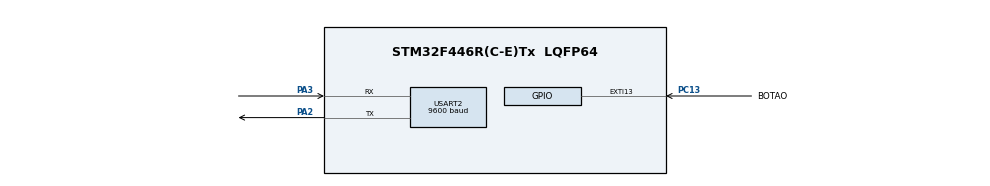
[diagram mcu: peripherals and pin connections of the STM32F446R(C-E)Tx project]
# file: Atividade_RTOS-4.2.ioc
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FREERTOS.CountingSemaphores01=MeuSemaforoContador,2,Dynamic,NULL,0
FREERTOS.Tasks01=Task_1,24,128,StartTask1,Default,NULL,Dynamic,NULL,NULL;Task_2,24,128,StartTask2,Default,NULL,Dynamic,NULL,NULL;Task_3,24,128,StartTask3,Default,NULL,Dynamic,NULL,NULL
FREERTOS.configUSE_NEWLIB_REENTRANT=1
Mcu.Family=STM32F4
Mcu.Name=STM32F446R(C-E)Tx
Mcu.Package=LQFP64
NVIC.EXTI15_10_IRQn=true\:5\:0\:false\:false\:true\:false\:true\:true\:true
NVIC.PriorityGroup=NVIC_PRIORITYGROUP_4
NVIC.TIM1_UP_TIM10_IRQn=true\:15\:0\:false\:false\:true\:false\:false\:true\:true
NVIC.TimeBase=TIM1_UP_TIM10_IRQn
NVIC.TimeBaseIP=TIM1
PA2.Mode=Asynchronous
PA2.Signal=USART2_TX
PA3.Mode=Asynchronous
PA3.Signal=USART2_RX
PC13.GPIO_Label=BOTAO
PC13.GPIO_PuPd=GPIO_NOPULL
PC13.Signal=GPXTI13
ProjectManager.HeapSize=0x200
ProjectManager.StackSize=0x400
ProjectManager.TargetToolchain=STM32CubeIDE
RCC.CortexFreq_Value=16000000
RCC.USBFreq_Value=96000000
RCC.VCOOutputFreq_Value=192000000
USART2.BaudRate=9600
USART2.VirtualMode=VM_ASYNC
VP_FREERTOS_VS_CMSIS_V2.Mode=CMSIS_V2
VP_SYS_VS_tim1.Mode=TIM1
board=custom

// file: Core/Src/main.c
/* USER CODE BEGIN Header */
/**
  ******************************************************************************
  * @file           : main.c
  * @brief          : Main program body
  ******************************************************************************
  * @attention
  *
  * Copyright (c) 2025 STMicroelectronics.
  * All rights reserved.
  *
  * This software is licensed under terms that can be found in the LICENSE file
  * in the root directory of this software component.
  * If no LICENSE file comes with this software, it is provided AS-IS.
  *
  ******************************************************************************
  */
/* USER CODE END Header */
#include "main.h"
#include "cmsis_os.h"

/* USER CODE BEGIN Includes */
#include <string.h>
/* USER CODE END Includes */

UART_HandleTypeDef huart2;

/* Definitions for Task_1 */
osThreadId_t Task_1Handle;
const osThreadAttr_t Task_1_attributes = {
  .name = "Task_1",
  .stack_size = 128 * 4,
  .priority = (osPriority_t) osPriorityNormal,
};
/* Definitions for Task_2 */
osThreadId_t Task_2Handle;
const osThreadAttr_t Task_2_attributes = {
  .name = "Task_2",
  .stack_size = 128 * 4,
  .priority = (osPriority_t) osPriorityNormal,
};
/* Definitions for Task_3 */
osThreadId_t Task_3Handle;
const osThreadAttr_t Task_3_attributes = {
  .name = "Task_3",
  .stack_size = 128 * 4,
  .priority = (osPriority_t) osPriorityNormal,
};
/* Definitions for MeuSemaforoContador */
osSemaphoreId_t MeuSemaforoContadorHandle;
const osSemaphoreAttr_t MeuSemaforoContador_attributes = {
  .name = "MeuSemaforoContador"
};

void SystemClock_Config(void);
static void MX_GPIO_Init(void);
static void MX_USART2_UART_Init(void);
void StartTask1(void *argument);
void StartTask2(void *argument);
void StartTask3(void *argument);

/* USER CODE BEGIN PFP */
void HAL_GPIO_EXTI_Callback(uint16_t PC13){
	osSemaphoreRelease(MeuSemaforoContadorHandle);
	char str [] = "Botao apertado, liberando semaforo \n";
	HAL_UART_Transmit(&huart2, (uint8_t *)str, strlen(str), HAL_MAX_DELAY);
}
/* USER CODE END PFP */

int main(void)
{

  /* MCU Configuration--------------------------------------------------------*/

  /* Reset of all peripherals, Initializes the Flash interface and the Systick. */
  HAL_Init();

  /* Configure the system clock */
  SystemClock_Config();

  /* Initialize all configured peripherals */
  MX_GPIO_Init();
  MX_USART2_UART_Init();

  /* Init scheduler */
  osKernelInitialize();

  /* Create the semaphores(s) */
  /* creation of MeuSemaforoContador */
  MeuSemaforoContadorHandle = osSemaphoreNew(2, 0, &MeuSemaforoContador_attributes);

  /* Create the thread(s) */
  /* creation of Task_1 */
  Task_1Handle = osThreadNew(StartTask1, NULL, &Task_1_attributes);

  /* creation of Task_2 */
  Task_2Handle = osThreadNew(StartTask2, NULL, &Task_2_attributes);

  /* creation of Task_3 */
  Task_3Handle = osThreadNew(StartTask3, NULL, &Task_3_attributes);

  /* Start scheduler */
  osKernelStart();

  /* We should never get here as control is now taken by the scheduler */

  /* Infinite loop */
  while (1)
  {

  }
}

void SystemClock_Config(void)
{
  RCC_OscInitTypeDef RCC_OscInitStruct = {0};
  RCC_ClkInitTypeDef RCC_ClkInitStruct = {0};

  /** Configure the main internal regulator output voltage
  */
  __HAL_RCC_PWR_CLK_ENABLE();
  __HAL_PWR_VOLTAGESCALING_CONFIG(PWR_REGULATOR_VOLTAGE_SCALE3);

  /** Initializes the RCC Oscillators according to the specified parameters
  * in the RCC_OscInitTypeDef structure.
  */
  RCC_OscInitStruct.OscillatorType = RCC_OSCILLATORTYPE_HSI;
  RCC_OscInitStruct.HSIState = RCC_HSI_ON;
  RCC_OscInitStruct.HSICalibrationValue = RCC_HSICALIBRATION_DEFAULT;
  RCC_OscInitStruct.PLL.PLLState = RCC_PLL_NONE;
  if (HAL_RCC_OscConfig(&RCC_OscInitStruct) != HAL_OK)
  {
    Error_Handler();
  }

  /** Initializes the CPU, AHB and APB buses clocks
  */
  RCC_ClkInitStruct.ClockType = RCC_CLOCKTYPE_HCLK|RCC_CLOCKTYPE_SYSCLK
                              |RCC_CLOCKTYPE_PCLK1|RCC_CLOCKTYPE_PCLK2;
  RCC_ClkInitStruct.SYSCLKSource = RCC_SYSCLKSOURCE_HSI;
  RCC_ClkInitStruct.AHBCLKDivider = RCC_SYSCLK_DIV1;
  RCC_ClkInitStruct.APB1CLKDivider = RCC_HCLK_DIV1;
  RCC_ClkInitStruct.APB2CLKDivider = RCC_HCLK_DIV1;

  if (HAL_RCC_ClockConfig(&RCC_ClkInitStruct, FLASH_LATENCY_0) != HAL_OK)
  {
    Error_Handler();
  }
}

static void MX_USART2_UART_Init(void)
{

  huart2.Instance = USART2;
  huart2.Init.BaudRate = 9600;
  huart2.Init.WordLength = UART_WORDLENGTH_8B;
  huart2.Init.StopBits = UART_STOPBITS_1;
  huart2.Init.Parity = UART_PARITY_NONE;
  huart2.Init.Mode = UART_MODE_TX_RX;
  huart2.Init.HwFlowCtl = UART_HWCONTROL_NONE;
  huart2.Init.OverSampling = UART_OVERSAMPLING_16;
  if (HAL_UART_Init(&huart2) != HAL_OK)
  {
    Error_Handler();
  }

}

static void MX_GPIO_Init(void)
{
  GPIO_InitTypeDef GPIO_InitStruct = {0};

  /* GPIO Ports Clock Enable */
  __HAL_RCC_GPIOC_CLK_ENABLE();
  __HAL_RCC_GPIOA_CLK_ENABLE();

  /*Configure GPIO pin : BOTAO_Pin */
  GPIO_InitStruct.Pin = BOTAO_Pin;
  GPIO_InitStruct.Mode = GPIO_MODE_IT_RISING;
  GPIO_InitStruct.Pull = GPIO_NOPULL;
  HAL_GPIO_Init(BOTAO_GPIO_Port, &GPIO_InitStruct);

  /* EXTI interrupt init*/
  HAL_NVIC_SetPriority(EXTI15_10_IRQn, 5, 0);
  HAL_NVIC_EnableIRQ(EXTI15_10_IRQn);

}

void StartTask1(void *argument)
{
  /* USER CODE BEGIN 5 */
    char Executando[] = "Task 1 Executando\n";
    char str[] = "Task 1 iniciando\n";

    HAL_UART_Transmit(&huart2, (uint8_t *) str, strlen(str), HAL_MAX_DELAY);
    osSemaphoreAcquire(MeuSemaforoContadorHandle, osWaitForever);
    // TRANSMITE QUANTOS ESPAÇOS TEM NO SEMÁFORO
    char buffer[30];
    uint32_t STRemINT;

    STRemINT = osSemaphoreGetCount(MeuSemaforoContadorHandle);

    // Convertendo para string
    sprintf(buffer, "Semaforo Count: %lu\r\n", STRemINT);

    // Transmite o buffer com a string formatada
    HAL_UART_Transmit(&huart2, (uint8_t *) buffer, strlen(buffer), HAL_MAX_DELAY);

    /* Infinite loop */
    for(;;)
    {
        // MOSTRA QUE ESTÁ EXECUTANDO
        HAL_UART_Transmit(&huart2, (uint8_t *) Executando, strlen(Executando), HAL_MAX_DELAY);
        osDelay(500);
    }
  /* USER CODE END 5 */
}

void StartTask2(void *argument)
{
  /* USER CODE BEGIN StartTask2 */
    char Executando[] = "Task 2 Executando\n";
    char str[] = "Task 2 iniciando\n";

    HAL_UART_Transmit(&huart2, (uint8_t *) str, strlen(str), HAL_MAX_DELAY);
    osSemaphoreAcquire(MeuSemaforoContadorHandle, osWaitForever);
    // TRANSMITE QUANTOS ESPAÇOS TEM NO SEMÁFORO
    char buffer[30];
    uint32_t STRemINT;

    STRemINT = osSemaphoreGetCount(MeuSemaforoContadorHandle);

    // Convertendo para string
    sprintf(buffer, "Semaforo Count: %lu\r\n", STRemINT);

    // Transmite o buffer com a string formatada
    HAL_UART_Transmit(&huart2, (uint8_t *) buffer, strlen(buffer), HAL_MAX_DELAY);

    /* Infinite loop */
    for(;;)
    {
        // MOSTRA QUE ESTÁ EXECUTANDO
        HAL_UART_Transmit(&huart2, (uint8_t *) Executando, strlen(Executando), HAL_MAX_DELAY);
        osDelay(500);
    }
  /* USER CODE END StartTask2 */
}

void StartTask3(void *argument)
{
  /* USER CODE BEGIN StartTask3 */
  /* Infinite loop */
    char Executando[] = "Task 3 Executando\n";
    char str[] = "Task 3 iniciando\n";

    HAL_UART_Transmit(&huart2, (uint8_t *) str, strlen(str), HAL_MAX_DELAY);
    osSemaphoreAcquire(MeuSemaforoContadorHandle, osWaitForever);
    // TRANSMITE QUANTOS ESPAÇOS TEM NO SEMÁFORO
    char buffer[30];
    uint32_t STRemINT;

    STRemINT = osSemaphoreGetCount(MeuSemaforoContadorHandle);

    // Convertendo para string
    sprintf(buffer, "Semaforo Count: %lu\r\n", STRemINT);

    // Transmite o buffer com a string formatada
    HAL_UART_Transmit(&huart2, (uint8_t *) buffer, strlen(buffer), HAL_MAX_DELAY);

    /* Infinite loop */
    for(;;)
    {
        // MOSTRA QUE ESTÁ EXECUTANDO
        HAL_UART_Transmit(&huart2, (uint8_t *) Executando, strlen(Executando), HAL_MAX_DELAY);
        osDelay(500);
    }
  /* USER CODE END StartTask3 */
}

void HAL_TIM_PeriodElapsedCallback(TIM_HandleTypeDef *htim)
{
  if (htim->Instance == TIM1)
  {
    HAL_IncTick();
  }
}

void Error_Handler(void)
{
  __disable_irq();
  while (1)
  {
  }
}

#ifdef  USE_FULL_ASSERT
/**
  * @brief  Reports the name of the source file and the source line number
  *         where the assert_param error has occurred.
  * @param  file: pointer to the source file name
  * @param  line: assert_param error line source number
  * @retval None
  */
void assert_failed(uint8_t *file, uint32_t line)
{
  /* USER CODE BEGIN 6 */
    char Executando[] = "Task 2 Executando\n";
    char str[] = "Task 2 iniciando\n";

    HAL_UART_Transmit(&huart2, (uint8_t *) str, strlen(str), HAL_MAX_DELAY);
    osSemaphoreAcquire(MeuSemaforoContadorHandle, osWaitForever);
    // TRANSMITE QUANTOS ESPAÇOS TEM NO SEMÁFORO
    char buffer[30];
    uint32_t STRemINT;

    STRemINT = osSemaphoreGetCount(MeuSemaforoContadorHandle);

    // Convertendo para string
    sprintf(buffer, "Semaforo Count: %lu\r\n", STRemINT);

    // Transmite o buffer com a string formatada
    HAL_UART_Transmit(&huart2, (uint8_t *) buffer, strlen(buffer), HAL_MAX_DELAY);

    /* Infinite loop */
    for(;;)
    {
        // MOSTRA QUE ESTÁ EXECUTANDO
        HAL_UART_Transmit(&huart2, (uint8_t *) Executando, strlen(Executando), HAL_MAX_DELAY);
        osDelay(500);
    }
  /* USER CODE END 6 */
}
#endif /* USE_FULL_ASSERT */
